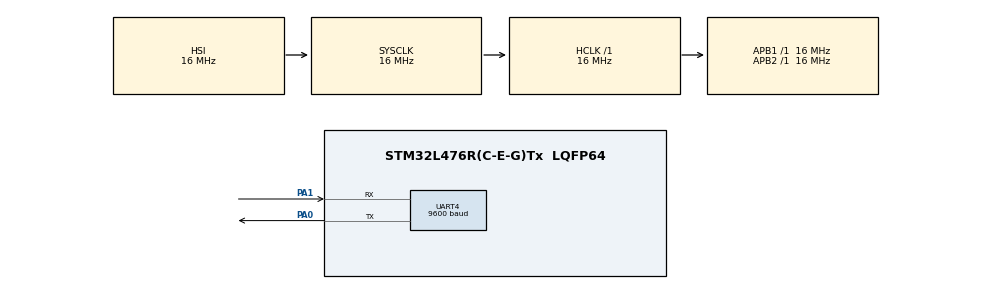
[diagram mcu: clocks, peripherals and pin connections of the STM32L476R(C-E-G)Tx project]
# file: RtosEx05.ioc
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FREERTOS.Queues01=Fila1,8,uint8_t,0,Dynamic,NULL,NULL
FREERTOS.Tasks01=Envia,24,128,Envia_fun,Default,NULL,Dynamic,NULL,NULL;Recebe,24,128,Recebe_fun,Default,NULL,Dynamic,NULL,NULL
FREERTOS.configUSE_NEWLIB_REENTRANT=1
Mcu.Family=STM32L4
Mcu.Name=STM32L476R(C-E-G)Tx
Mcu.Package=LQFP64
NVIC.PriorityGroup=NVIC_PRIORITYGROUP_4
NVIC.TIM1_UP_TIM16_IRQn=true\:15\:0\:false\:false\:true\:false\:false\:true\:true
NVIC.TimeBase=TIM1_UP_TIM16_IRQn
NVIC.TimeBaseIP=TIM1
PA0.Mode=Asynchronous
PA0.Signal=UART4_TX
PA1.Mode=Asynchronous
PA1.Signal=UART4_RX
ProjectManager.HeapSize=0x200
ProjectManager.StackSize=0x400
ProjectManager.TargetToolchain=STM32CubeIDE
RCC.ADCFreq_Value=64000000
RCC.AHBFreq_Value=16000000
RCC.APB1Freq_Value=16000000
RCC.APB1TimFreq_Value=16000000
RCC.APB2Freq_Value=16000000
RCC.APB2TimFreq_Value=16000000
RCC.CortexFreq_Value=16000000
RCC.HCLKFreq_Value=16000000
RCC.HSE_VALUE=8000000
RCC.HSI_VALUE=16000000
RCC.MSI_VALUE=4000000
RCC.PLLN=10
RCC.PLLSourceVirtual=RCC_PLLSOURCE_HSI
RCC.PREFETCH_ENABLE=1
RCC.SYSCLKFreq_VALUE=16000000
RCC.SYSCLKSource=RCC_SYSCLKSOURCE_HSI
RCC.USBFreq_Value=64000000
RCC.VCOOutputFreq_Value=160000000
UART4.BaudRate=9600
UART4.Mode=MODE_TX
VP_FREERTOS_VS_CMSIS_V2.Mode=CMSIS_V2
VP_SYS_VS_tim1.Mode=TIM1
board=NUCLEO-L476RG

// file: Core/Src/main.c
/* USER CODE BEGIN Header */
/**
  ******************************************************************************
  * @file           : main.c
  * @brief          : Main program body
  ******************************************************************************
  * @attention
  *
  * Copyright (c) 2025 STMicroelectronics.
  * All rights reserved.
  *
  * This software is licensed under terms that can be found in the LICENSE file
  * in the root directory of this software component.
  * If no LICENSE file comes with this software, it is provided AS-IS.
  *
  ******************************************************************************
  */
/* USER CODE END Header */
#include "main.h"
#include "cmsis_os.h"

/* USER CODE BEGIN Includes */
#include <stdio.h>
/* USER CODE END Includes */

UART_HandleTypeDef huart4;

/* Definitions for Envia */
osThreadId_t EnviaHandle;
const osThreadAttr_t Envia_attributes = {
  .name = "Envia",
  .stack_size = 128 * 4,
  .priority = (osPriority_t) osPriorityNormal,
};
/* Definitions for Recebe */
osThreadId_t RecebeHandle;
const osThreadAttr_t Recebe_attributes = {
  .name = "Recebe",
  .stack_size = 128 * 4,
  .priority = (osPriority_t) osPriorityNormal,
};
/* Definitions for Fila1 */
osMessageQueueId_t Fila1Handle;
const osMessageQueueAttr_t Fila1_attributes = {
  .name = "Fila1"
};

void SystemClock_Config(void);
static void MX_GPIO_Init(void);
static void MX_UART4_Init(void);
void Envia_fun(void *argument);
void Recebe_fun(void *argument);

int main(void)
{

  /* MCU Configuration--------------------------------------------------------*/

  /* Reset of all peripherals, Initializes the Flash interface and the Systick. */
  HAL_Init();

  /* Configure the system clock */
  SystemClock_Config();

  /* Initialize all configured peripherals */
  MX_GPIO_Init();
  MX_UART4_Init();

  /* Init scheduler */
  osKernelInitialize();

  /* Create the queue(s) */
  /* creation of Fila1 */
  Fila1Handle = osMessageQueueNew (8, sizeof(uint8_t), &Fila1_attributes);

  /* Create the thread(s) */
  /* creation of Envia */
  EnviaHandle = osThreadNew(Envia_fun, NULL, &Envia_attributes);

  /* creation of Recebe */
  RecebeHandle = osThreadNew(Recebe_fun, NULL, &Recebe_attributes);

  /* Start scheduler */
  osKernelStart();

  /* We should never get here as control is now taken by the scheduler */

  /* Infinite loop */
  while (1)
  {

  }
}

void SystemClock_Config(void)
{
  RCC_OscInitTypeDef RCC_OscInitStruct = {0};
  RCC_ClkInitTypeDef RCC_ClkInitStruct = {0};

  /** Configure the main internal regulator output voltage
  */
  if (HAL_PWREx_ControlVoltageScaling(PWR_REGULATOR_VOLTAGE_SCALE1) != HAL_OK)
  {
    Error_Handler();
  }

  /** Initializes the RCC Oscillators according to the specified parameters
  * in the RCC_OscInitTypeDef structure.
  */
  RCC_OscInitStruct.OscillatorType = RCC_OSCILLATORTYPE_HSI;
  RCC_OscInitStruct.HSIState = RCC_HSI_ON;
  RCC_OscInitStruct.HSICalibrationValue = RCC_HSICALIBRATION_DEFAULT;
  RCC_OscInitStruct.PLL.PLLState = RCC_PLL_NONE;
  if (HAL_RCC_OscConfig(&RCC_OscInitStruct) != HAL_OK)
  {
    Error_Handler();
  }

  /** Initializes the CPU, AHB and APB buses clocks
  */
  RCC_ClkInitStruct.ClockType = RCC_CLOCKTYPE_HCLK|RCC_CLOCKTYPE_SYSCLK
                              |RCC_CLOCKTYPE_PCLK1|RCC_CLOCKTYPE_PCLK2;
  RCC_ClkInitStruct.SYSCLKSource = RCC_SYSCLKSOURCE_HSI;
  RCC_ClkInitStruct.AHBCLKDivider = RCC_SYSCLK_DIV1;
  RCC_ClkInitStruct.APB1CLKDivider = RCC_HCLK_DIV1;
  RCC_ClkInitStruct.APB2CLKDivider = RCC_HCLK_DIV1;

  if (HAL_RCC_ClockConfig(&RCC_ClkInitStruct, FLASH_LATENCY_0) != HAL_OK)
  {
    Error_Handler();
  }
}

static void MX_UART4_Init(void)
{

  huart4.Instance = UART4;
  huart4.Init.BaudRate = 9600;
  huart4.Init.WordLength = UART_WORDLENGTH_8B;
  huart4.Init.StopBits = UART_STOPBITS_1;
  huart4.Init.Parity = UART_PARITY_NONE;
  huart4.Init.Mode = UART_MODE_TX;
  huart4.Init.HwFlowCtl = UART_HWCONTROL_NONE;
  huart4.Init.OverSampling = UART_OVERSAMPLING_16;
  huart4.Init.OneBitSampling = UART_ONE_BIT_SAMPLE_DISABLE;
  huart4.AdvancedInit.AdvFeatureInit = UART_ADVFEATURE_NO_INIT;
  if (HAL_UART_Init(&huart4) != HAL_OK)
  {
    Error_Handler();
  }

}

static void MX_GPIO_Init(void)
{

  /* GPIO Ports Clock Enable */
  __HAL_RCC_GPIOA_CLK_ENABLE();

}

void Envia_fun(void *argument)
{
  /* USER CODE BEGIN 5 */
	uint8_t dados_tx;
  /* Infinite loop */
  for(;;)
  {
    osDelay(1000);

    // Teste 1
//    dados_tx = 0x61;
//    osMessageQueuePut(Fila1Handle, &dados_tx, 0, 1000); // enviando os dados p/ fila

    // Teste 2
	dados_tx = 100;
	osMessageQueuePut(Fila1Handle, &dados_tx, 0, 1000); // enviando os dados p/ fila

  }
  /* USER CODE END 5 */
}

void Recebe_fun(void *argument)
{
  /* USER CODE BEGIN Recebe_fun */
	uint8_t dados_rx;
	uint8_t buffer[5];
  /* Infinite loop */
  for(;;)
  {
    osDelay(1000);
    // Teste 1
//    osMessageQueueGet(Fila1Handle, &dados_rx, NULL, osWaitForever); // pega o dado da fila
//    HAL_UART_Transmit(&huart4, &dados_rx, 1, 100);

    // Teste 2
    osMessageQueueGet(Fila1Handle, &dados_rx, NULL, osWaitForever); // pega o dado da fila
    dados_rx = dados_rx + 5;
    sprintf(buffer, "%04u\n", dados_rx); // convertendo para hexadecimal
	HAL_UART_Transmit(&huart4, buffer, 5, 100);

  }
  /* USER CODE END Recebe_fun */
}

void HAL_TIM_PeriodElapsedCallback(TIM_HandleTypeDef *htim)
{
  if (htim->Instance == TIM1) {
    HAL_IncTick();
  }
}

void Error_Handler(void)
{
  __disable_irq();
  while (1)
  {
  }
}
